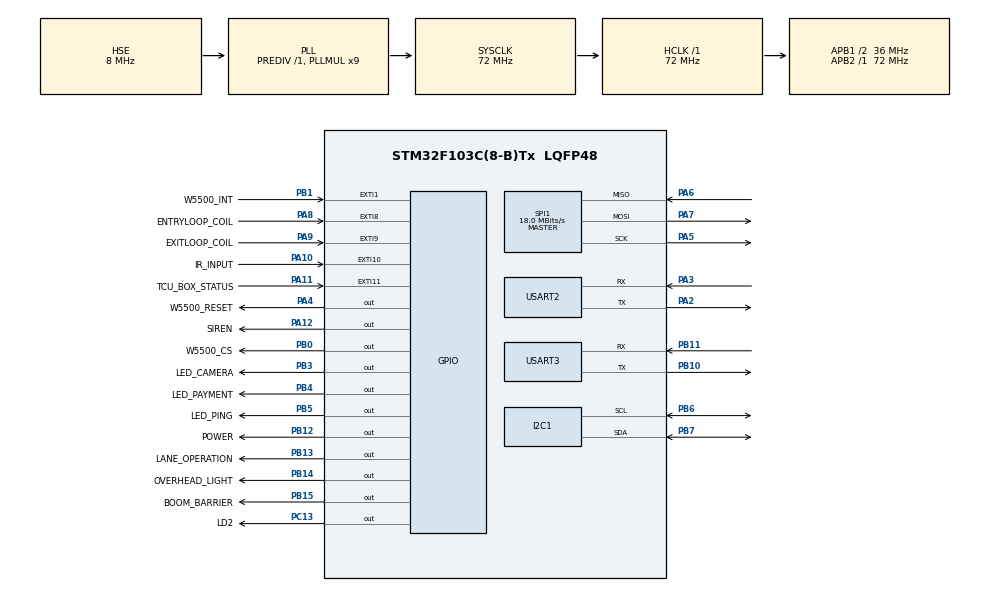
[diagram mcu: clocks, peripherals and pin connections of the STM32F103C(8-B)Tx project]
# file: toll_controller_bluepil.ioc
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Dma.Request0=USART2_RX
Dma.Request1=USART2_TX
Dma.USART2_RX.0.Direction=DMA_PERIPH_TO_MEMORY
Dma.USART2_RX.0.Instance=DMA1_Channel6
Dma.USART2_RX.0.MemDataAlignment=DMA_MDATAALIGN_BYTE
Dma.USART2_RX.0.MemInc=DMA_MINC_ENABLE
Dma.USART2_RX.0.Mode=DMA_NORMAL
Dma.USART2_RX.0.PeriphDataAlignment=DMA_PDATAALIGN_BYTE
Dma.USART2_RX.0.PeriphInc=DMA_PINC_DISABLE
Dma.USART2_RX.0.Priority=DMA_PRIORITY_LOW
Dma.USART2_TX.1.Direction=DMA_MEMORY_TO_PERIPH
Dma.USART2_TX.1.Instance=DMA1_Channel7
Dma.USART2_TX.1.MemDataAlignment=DMA_MDATAALIGN_BYTE
Dma.USART2_TX.1.MemInc=DMA_MINC_ENABLE
Dma.USART2_TX.1.Mode=DMA_NORMAL
Dma.USART2_TX.1.PeriphDataAlignment=DMA_PDATAALIGN_BYTE
Dma.USART2_TX.1.PeriphInc=DMA_PINC_DISABLE
Dma.USART2_TX.1.Priority=DMA_PRIORITY_LOW
Mcu.Family=STM32F1
Mcu.Name=STM32F103C(8-B)Tx
Mcu.Package=LQFP48
NVIC.DMA1_Channel6_IRQn=true\:0\:0\:false\:false\:true\:false\:true\:true
NVIC.DMA1_Channel7_IRQn=true\:0\:0\:false\:false\:true\:false\:true\:true
NVIC.EXTI15_10_IRQn=true\:0\:0\:false\:false\:true\:true\:true\:true
NVIC.EXTI1_IRQn=true\:0\:0\:false\:false\:true\:true\:true\:true
NVIC.EXTI9_5_IRQn=true\:0\:0\:false\:false\:true\:true\:true\:true
NVIC.PriorityGroup=NVIC_PRIORITYGROUP_4
NVIC.TIM1_UP_IRQn=true\:0\:0\:false\:false\:true\:true\:true\:true
NVIC.TIM2_IRQn=true\:0\:0\:false\:false\:true\:true\:true\:true
NVIC.TIM3_IRQn=true\:0\:0\:false\:false\:true\:true\:true\:true
NVIC.TIM4_IRQn=true\:0\:0\:false\:false\:true\:true\:true\:true
NVIC.USART2_IRQn=true\:0\:0\:false\:false\:true\:true\:true\:true
PA10.GPIO_Label=IR_INPUT
PA10.GPIO_ModeDefaultEXTI=GPIO_MODE_IT_RISING_FALLING
PA10.GPIO_PuPd=GPIO_PULLDOWN
PA10.Signal=GPXTI10
PA11.GPIO_Label=TCU_BOX_STATUS
PA11.GPIO_ModeDefaultEXTI=GPIO_MODE_IT_RISING_FALLING
PA11.GPIO_PuPd=GPIO_PULLDOWN
PA11.Signal=GPXTI11
PA12.GPIO_Label=SIREN
PA12.Signal=GPIO_Output
PA13.Mode=Serial_Wire
PA13.Signal=SYS_JTMS-SWDIO
PA14.Mode=Serial_Wire
PA14.Signal=SYS_JTCK-SWCLK
PA2.Mode=Asynchronous
PA2.Signal=USART2_TX
PA3.Mode=Asynchronous
PA3.Signal=USART2_RX
PA4.GPIO_Label=W5500_RESET
PA4.Signal=GPIO_Output
PA5.Mode=Full_Duplex_Master
PA5.Signal=SPI1_SCK
PA6.Mode=Full_Duplex_Master
PA6.Signal=SPI1_MISO
PA7.Mode=Full_Duplex_Master
PA7.Signal=SPI1_MOSI
PA8.GPIO_Label=ENTRYLOOP_COIL
PA8.GPIO_ModeDefaultEXTI=GPIO_MODE_IT_RISING_FALLING
PA8.GPIO_PuPd=GPIO_PULLDOWN
PA8.Signal=GPXTI8
PA9.GPIO_Label=EXITLOOP_COIL
PA9.GPIO_ModeDefaultEXTI=GPIO_MODE_IT_RISING_FALLING
PA9.GPIO_PuPd=GPIO_NOPULL
PA9.Signal=GPXTI9
PB0.GPIO_Label=W5500_CS
PB0.Signal=GPIO_Output
PB1.GPIO_Label=W5500_INT
PB1.GPIO_ModeDefaultEXTI=GPIO_MODE_IT_FALLING
PB1.GPIO_PuPd=GPIO_PULLUP
PB1.Signal=GPXTI1
PB10.Mode=Asynchronous
PB10.Signal=USART3_TX
PB11.Mode=Asynchronous
PB11.Signal=USART3_RX
PB12.GPIO_Label=POWER
PB12.Signal=GPIO_Output
PB13.GPIO_Label=LANE_OPERATION
PB13.Signal=GPIO_Output
PB14.GPIO_Label=OVERHEAD_LIGHT
PB14.Signal=GPIO_Output
PB15.GPIO_Label=BOOM_BARRIER
PB15.Signal=GPIO_Output
PB3.GPIO_Label=LED_CAMERA
PB3.GPIO_PuPd=GPIO_PULLDOWN
PB3.Signal=GPIO_Output
PB4.GPIO_Label=LED_PAYMENT
PB4.GPIO_PuPd=GPIO_PULLDOWN
PB4.Signal=GPIO_Output
PB5.GPIO_Label=LED_PING
PB5.GPIO_PuPd=GPIO_PULLDOWN
PB5.Signal=GPIO_Output
PB6.Mode=I2C
PB6.Signal=I2C1_SCL
PB7.Mode=I2C
PB7.Signal=I2C1_SDA
PC13-TAMPER-RTC.GPIO_Label=LD2
PC13-TAMPER-RTC.Signal=GPIO_Output
PD0-OSC_IN.Mode=HSE-External-Oscillator
PD0-OSC_IN.Signal=RCC_OSC_IN
PD1-OSC_OUT.Mode=HSE-External-Oscillator
PD1-OSC_OUT.Signal=RCC_OSC_OUT
ProjectManager.HeapSize=0x200
ProjectManager.StackSize=0x400
ProjectManager.TargetToolchain=STM32CubeIDE
RCC.AHBFreq_Value=72000000
RCC.APB1CLKDivider=RCC_HCLK_DIV2
RCC.APB1Freq_Value=36000000
RCC.APB1TimFreq_Value=72000000
RCC.APB2Freq_Value=72000000
RCC.APB2TimFreq_Value=72000000
RCC.HCLKFreq_Value=72000000
RCC.PLLMUL=RCC_PLL_MUL9
RCC.PLLSourceVirtual=RCC_PLLSOURCE_HSE
RCC.SYSCLKFreq_VALUE=72000000
RCC.SYSCLKSource=RCC_SYSCLKSOURCE_PLLCLK
RCC.USBFreq_Value=72000000
SPI1.BaudRatePrescaler=SPI_BAUDRATEPRESCALER_4
SPI1.CalculateBaudRate=18.0 MBits/s
SPI1.Direction=SPI_DIRECTION_2LINES
SPI1.Mode=SPI_MODE_MASTER
SPI1.VirtualType=VM_MASTER
TIM1.Period=299
TIM1.Prescaler=7199
TIM2.Period=299
TIM2.Prescaler=7199
TIM3.Period=299
TIM3.Prescaler=7199
TIM4.Period=299
TIM4.Prescaler=7199
USART2.VirtualMode=VM_ASYNC
USART3.VirtualMode=VM_ASYNC
VP_TIM1_VS_ClockSourceINT.Mode=Internal
VP_TIM2_VS_ClockSourceINT.Mode=Internal
VP_TIM3_VS_ClockSourceINT.Mode=Internal
VP_TIM4_VS_ClockSourceINT.Mode=Internal
board=custom

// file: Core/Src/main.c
/* USER CODE BEGIN Header */
/**
  ******************************************************************************
  * @file           : main.c
  * @brief          : Main program body
  ******************************************************************************
  * @attention
  *
  * Copyright (c) 2024 STMicroelectronics.
  * All rights reserved.
  *
  * This software is licensed under terms that can be found in the LICENSE file
  * in the root directory of this software component.
  * If no LICENSE file comes with this software, it is provided AS-IS.
  *
  ******************************************************************************
  */
/* USER CODE END Header */
#include "main.h"
#include "dma.h"
#include "i2c.h"
#include "spi.h"
#include "tim.h"
#include "usart.h"
#include "gpio.h"

/* USER CODE BEGIN Includes */
#include "app_main.h"
#include "commands.h"
#include "uart_manager.h"

/* USER CODE END Includes */

void SystemClock_Config(void);

int main(void)
{

  /* MCU Configuration--------------------------------------------------------*/

  /* Reset of all peripherals, Initializes the Flash interface and the Systick. */
  HAL_Init();

  /* Configure the system clock */
  SystemClock_Config();

  /* Initialize all configured peripherals */
  MX_GPIO_Init();
  MX_DMA_Init();
  MX_SPI1_Init();
  MX_USART2_UART_Init();
  MX_USART3_UART_Init();
  MX_I2C1_Init();
  MX_TIM1_Init();
  MX_TIM2_Init();
  MX_TIM3_Init();
  MX_TIM4_Init();
  /* USER CODE BEGIN 2 */

  init();
  //U_initialize();
  /* USER CODE END 2 */

  /* Infinite loop */
  /* USER CODE BEGIN WHILE */
  while (1)
  {

	  loop();
    /* USER CODE END WHILE */

  }
}

void SystemClock_Config(void)
{
  RCC_OscInitTypeDef RCC_OscInitStruct = {0};
  RCC_ClkInitTypeDef RCC_ClkInitStruct = {0};

  /** Initializes the RCC Oscillators according to the specified parameters
  * in the RCC_OscInitTypeDef structure.
  */
  RCC_OscInitStruct.OscillatorType = RCC_OSCILLATORTYPE_HSE;
  RCC_OscInitStruct.HSEState = RCC_HSE_ON;
  RCC_OscInitStruct.HSEPredivValue = RCC_HSE_PREDIV_DIV1;
  RCC_OscInitStruct.HSIState = RCC_HSI_ON;
  RCC_OscInitStruct.PLL.PLLState = RCC_PLL_ON;
  RCC_OscInitStruct.PLL.PLLSource = RCC_PLLSOURCE_HSE;
  RCC_OscInitStruct.PLL.PLLMUL = RCC_PLL_MUL9;
  if (HAL_RCC_OscConfig(&RCC_OscInitStruct) != HAL_OK)
  {
    Error_Handler();
  }

  /** Initializes the CPU, AHB and APB buses clocks
  */
  RCC_ClkInitStruct.ClockType = RCC_CLOCKTYPE_HCLK|RCC_CLOCKTYPE_SYSCLK
                              |RCC_CLOCKTYPE_PCLK1|RCC_CLOCKTYPE_PCLK2;
  RCC_ClkInitStruct.SYSCLKSource = RCC_SYSCLKSOURCE_PLLCLK;
  RCC_ClkInitStruct.AHBCLKDivider = RCC_SYSCLK_DIV1;
  RCC_ClkInitStruct.APB1CLKDivider = RCC_HCLK_DIV2;
  RCC_ClkInitStruct.APB2CLKDivider = RCC_HCLK_DIV1;

  if (HAL_RCC_ClockConfig(&RCC_ClkInitStruct, FLASH_LATENCY_2) != HAL_OK)
  {
    Error_Handler();
  }
}

void Error_Handler(void)
{
  __disable_irq();
  while (1)
  {
  }
}
